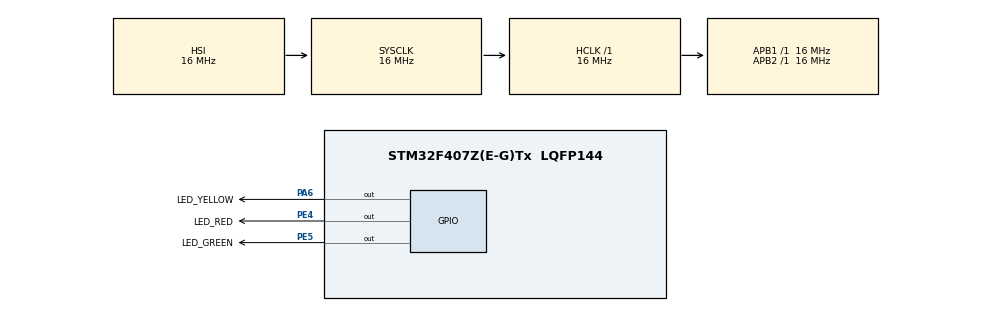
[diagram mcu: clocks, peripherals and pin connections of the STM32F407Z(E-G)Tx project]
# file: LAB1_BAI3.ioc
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Mcu.Family=STM32F4
Mcu.Name=STM32F407Z(E-G)Tx
Mcu.Package=LQFP144
NVIC.PriorityGroup=NVIC_PRIORITYGROUP_4
PA13.Mode=Serial_Wire
PA13.Signal=SYS_JTMS-SWDIO
PA14.Mode=Serial_Wire
PA14.Signal=SYS_JTCK-SWCLK
PA6.GPIO_Label=LED_YELLOW
PA6.Signal=GPIO_Output
PE4.GPIO_Label=LED_RED
PE4.Signal=GPIO_Output
PE5.GPIO_Label=LED_GREEN
PE5.Signal=GPIO_Output
PH0-OSC_IN.Mode=HSE-External-Oscillator
PH0-OSC_IN.Signal=RCC_OSC_IN
PH1-OSC_OUT.Mode=HSE-External-Oscillator
PH1-OSC_OUT.Signal=RCC_OSC_OUT
ProjectManager.HeapSize=0x200
ProjectManager.StackSize=0x400
ProjectManager.TargetToolchain=STM32CubeIDE
RCC.AHBFreq_Value=16000000
RCC.APB1Freq_Value=16000000
RCC.APB2Freq_Value=16000000
RCC.CortexFreq_Value=16000000
RCC.HSE_VALUE=8000000
RCC.HSI_VALUE=16000000
RCC.LSE_VALUE=32768
RCC.SYSCLKFreq_VALUE=16000000
RCC.VCOOutputFreq_Value=192000000
board=custom

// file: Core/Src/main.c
/* USER CODE BEGIN Header */
/**
  ******************************************************************************
  * @file           : main.c
  * @brief          : Main program body
  ******************************************************************************
  * @attention
  *
  * <h2><center>&copy; Copyright (c) 2024 STMicroelectronics.
  * All rights reserved.</center></h2>
  *
  * This software component is licensed by ST under BSD 3-Clause license,
  * the "License"; You may not use this file except in compliance with the
  * License. You may obtain a copy of the License at:
  *                        opensource.org/licenses/BSD-3-Clause
  *
  ******************************************************************************
  */
/* USER CODE END Header */
#include "main.h"

/* USER CODE BEGIN Includes */
#define	RED 	0
#define GREEN 	1
#define YELLOW	2
#define	ON 		1
#define OFF 	0
/* USER CODE END Includes */

void SystemClock_Config(void);
static void MX_GPIO_Init(void);

int main(void)
{

  /* MCU Configuration--------------------------------------------------------*/

  /* Reset of all peripherals, Initializes the Flash interface and the Systick. */
  HAL_Init();

  /* Configure the system clock */
  SystemClock_Config();

  /* Initialize all configured peripherals */
  MX_GPIO_Init();
  /* USER CODE BEGIN 2 */
    int count = 0;
    int state = RED;
  /* USER CODE END 2 */

  /* Infinite loop */
  /* USER CODE BEGIN WHILE */
    while (1)
    {
  	  if (count <= 0)
  	  {
  		  if (state == RED)
  		  {
  			  HAL_GPIO_WritePin(LED_RED_GPIO_Port, LED_RED_Pin, OFF);
  			  HAL_GPIO_WritePin(LED_GREEN_GPIO_Port, LED_GREEN_Pin, ON);
  			  HAL_GPIO_WritePin(LED_YELLOW_GPIO_Port, LED_YELLOW_Pin, ON);
  			  count = 3;
  			  state = GREEN;
  		  }
  		  else if (state == GREEN)
  		  {
  			  HAL_GPIO_WritePin(LED_RED_GPIO_Port, LED_RED_Pin, OFF);
			  HAL_GPIO_WritePin(LED_GREEN_GPIO_Port, LED_GREEN_Pin, OFF);
			  HAL_GPIO_WritePin(LED_YELLOW_GPIO_Port, LED_YELLOW_Pin, OFF);
			  count = 1;
			  state = YELLOW;
  		  }
  		  else if (state == YELLOW){
  			  HAL_GPIO_WritePin(LED_RED_GPIO_Port, LED_RED_Pin, ON);
			  HAL_GPIO_WritePin(LED_GREEN_GPIO_Port, LED_GREEN_Pin, OFF);
			  HAL_GPIO_WritePin(LED_YELLOW_GPIO_Port, LED_YELLOW_Pin, ON);
			  count = 5;
			  state = RED;
  		  }
  	  }
  	  count = count - 1;
  	  HAL_Delay(1000);
    /* USER CODE END WHILE */

  }
}

void SystemClock_Config(void)
{
  RCC_OscInitTypeDef RCC_OscInitStruct = {0};
  RCC_ClkInitTypeDef RCC_ClkInitStruct = {0};

  /** Configure the main internal regulator output voltage
  */
  __HAL_RCC_PWR_CLK_ENABLE();
  __HAL_PWR_VOLTAGESCALING_CONFIG(PWR_REGULATOR_VOLTAGE_SCALE1);
  /** Initializes the RCC Oscillators according to the specified parameters
  * in the RCC_OscInitTypeDef structure.
  */
  RCC_OscInitStruct.OscillatorType = RCC_OSCILLATORTYPE_HSI;
  RCC_OscInitStruct.HSIState = RCC_HSI_ON;
  RCC_OscInitStruct.HSICalibrationValue = RCC_HSICALIBRATION_DEFAULT;
  RCC_OscInitStruct.PLL.PLLState = RCC_PLL_NONE;
  if (HAL_RCC_OscConfig(&RCC_OscInitStruct) != HAL_OK)
  {
    Error_Handler();
  }
  /** Initializes the CPU, AHB and APB buses clocks
  */
  RCC_ClkInitStruct.ClockType = RCC_CLOCKTYPE_HCLK|RCC_CLOCKTYPE_SYSCLK
                              |RCC_CLOCKTYPE_PCLK1|RCC_CLOCKTYPE_PCLK2;
  RCC_ClkInitStruct.SYSCLKSource = RCC_SYSCLKSOURCE_HSI;
  RCC_ClkInitStruct.AHBCLKDivider = RCC_SYSCLK_DIV1;
  RCC_ClkInitStruct.APB1CLKDivider = RCC_HCLK_DIV1;
  RCC_ClkInitStruct.APB2CLKDivider = RCC_HCLK_DIV1;

  if (HAL_RCC_ClockConfig(&RCC_ClkInitStruct, FLASH_LATENCY_0) != HAL_OK)
  {
    Error_Handler();
  }
}

static void MX_GPIO_Init(void)
{
  GPIO_InitTypeDef GPIO_InitStruct = {0};

  /* GPIO Ports Clock Enable */
  __HAL_RCC_GPIOE_CLK_ENABLE();
  __HAL_RCC_GPIOH_CLK_ENABLE();
  __HAL_RCC_GPIOA_CLK_ENABLE();

  /*Configure GPIO pin Output Level */
  HAL_GPIO_WritePin(GPIOE, LED_RED_Pin|LED_GREEN_Pin, GPIO_PIN_RESET);

  /*Configure GPIO pin Output Level */
  HAL_GPIO_WritePin(LED_YELLOW_GPIO_Port, LED_YELLOW_Pin, GPIO_PIN_RESET);

  /*Configure GPIO pins : LED_RED_Pin LED_GREEN_Pin */
  GPIO_InitStruct.Pin = LED_RED_Pin|LED_GREEN_Pin;
  GPIO_InitStruct.Mode = GPIO_MODE_OUTPUT_PP;
  GPIO_InitStruct.Pull = GPIO_NOPULL;
  GPIO_InitStruct.Speed = GPIO_SPEED_FREQ_LOW;
  HAL_GPIO_Init(GPIOE, &GPIO_InitStruct);

  /*Configure GPIO pin : LED_YELLOW_Pin */
  GPIO_InitStruct.Pin = LED_YELLOW_Pin;
  GPIO_InitStruct.Mode = GPIO_MODE_OUTPUT_PP;
  GPIO_InitStruct.Pull = GPIO_NOPULL;
  GPIO_InitStruct.Speed = GPIO_SPEED_FREQ_LOW;
  HAL_GPIO_Init(LED_YELLOW_GPIO_Port, &GPIO_InitStruct);

}

void Error_Handler(void)
{
  __disable_irq();
  while (1)
  {
  }
}

/************************ (C) COPYRIGHT STMicroelectronics *****END OF FILE****/
